AUTOSAR XML (schema 4-2-2)
package /Components
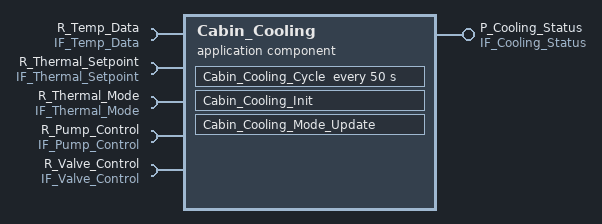
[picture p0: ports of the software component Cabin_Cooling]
  application sw component type Cabin_Cooling
    provide port P_Cooling_Status: provided-interface=IF_Cooling_Status
    5 x require port:
      R_Temp_Data: required-interface=IF_Temp_Data
      R_Thermal_Setpoint: required-interface=IF_Thermal_Setpoint
      R_Thermal_Mode: required-interface=IF_Thermal_Mode
      R_Pump_Control: required-interface=IF_Pump_Control
      R_Valve_Control: required-interface=IF_Valve_Control
    behavior Cabin_Cooling_InternalBehavior
      data received event Cabin_Cooling_Setpoint_Update: start-on-event=Cabin_Cooling_Cycle
      init event Cabin_Cooling_Init_Event: start-on-event=Cabin_Cooling_Init
      swc mode switch event Cabin_Cooling_Mode_Switch: start-on-event=Cabin_Cooling_Mode_Update, activation=ON-TRANSITION, mode=ThermalModeGroup.R_Thermal_Mode.CabinPriority
      timing event Cabin_Cooling_Periodic_50ms: start-on-event=Cabin_Cooling_Cycle, period=50
      runnable Cabin_Cooling_Init: mode-access-point=R_Thermal_Mode.ThermalModeGroup
        data-read-access:
          access VA_Read_t_cabin_ambient_Init: accessed-variable=R_Temp_Data.t_cabin_ambient
          access VA_Read_target_cabin_duty_Init: accessed-variable=R_Thermal_Setpoint.target_cabin_evap_duty
        data-receive-point-by-values:
          access VA_Rcv_target_cabin_duty_Init: accessed-variable=R_Thermal_Setpoint.target_cabin_evap_duty
        data-send-points:
          access VA_Send_CabinStatus_Init: accessed-variable=P_Cooling_Status.cabin_cooling_status
        data-write-access:
          access VA_Write_CabinStatus_Init: accessed-variable=P_Cooling_Status.cabin_cooling_status
        sync call SCP_GetPumpStatus_Init: operation=R_Pump_Control.op_get_pump_status, timeout=50
      runnable Cabin_Cooling_Cycle: mode-access-point=R_Thermal_Mode.ThermalModeGroup
        data-read-access:
          4 x access:
            VA_Read_t_evap_outlet_Cycle: accessed-variable=R_Temp_Data.t_evap_outlet
            VA_Read_t_cabin_ambient_Cycle: accessed-variable=R_Temp_Data.t_cabin_ambient
            VA_Read_t_heater_core_Cycle: accessed-variable=R_Temp_Data.t_heater_core
            VA_Read_target_cabin_duty_Cycle: accessed-variable=R_Thermal_Setpoint.target_cabin_evap_duty
        data-receive-point-by-values:
          access VA_Rcv_target_cabin_duty_Cycle: accessed-variable=R_Thermal_Setpoint.target_cabin_evap_duty
        data-send-points:
          access VA_Send_CabinStatus_Cycle: accessed-variable=P_Cooling_Status.cabin_cooling_status
        data-write-access:
          access VA_Write_CabinStatus_Cycle: accessed-variable=P_Cooling_Status.cabin_cooling_status
        sync call SCP_SetPumpSpeed_Cycle: operation=R_Pump_Control.op_set_pump_speed, timeout=50
        sync call SCP_SetValvePosition_Cycle: operation=R_Valve_Control.op_set_valve_position, timeout=50
      runnable Cabin_Cooling_Mode_Update: mode-access-point=R_Thermal_Mode.ThermalModeGroup
        data-read-access:
          access VA_Read_t_evap_outlet_Mode: accessed-variable=R_Temp_Data.t_evap_outlet
        data-receive-point-by-values:
          access VA_Rcv_target_cabin_duty_Mode: accessed-variable=R_Thermal_Setpoint.target_cabin_evap_duty
        data-send-points:
          access VA_Send_CabinStatus_Mode: accessed-variable=P_Cooling_Status.cabin_cooling_status
        data-write-access:
          access VA_Write_CabinStatus_Mode: accessed-variable=P_Cooling_Status.cabin_cooling_status
        sync call SCP_GetValveStatus_Mode: operation=R_Valve_Control.op_get_valve_status, timeout=50
